VERSION "HIPBNYYYYYYYYYYYYYYYYYYYYYYYYYYYYYYYYYYYYY/4/%%%/4/'%**4YYY///"

NS_ :

BS_:

BU_: WS200 MCN_Powertrain Front_MCN Mid_MCN Rear_MCN IMU_MCN BIM1 BIM2 BIM3 BIM4 Computer BIM5 Rider_Controls

BO_ 1024 WS200IDInfo: 8 WS200
 SG_ TritiumID : 0|32@1+ (1,0) [0|0] "" Vector__XXX
 SG_ SerialNumber : 32|32@1+ (1,0) [0|0] "" Vector__XXX

BO_ 1025 WS200Status: 8 WS200
 SG_ ActiveMotor : 32|16@1+ (1,0) [0|0] "" Vector__XXX
 SG_ TransmitErrorCount : 48|8@1+ (1,0) [0|0] "" Vector__XXX
 SG_ ReceiveErrorCount : 56|8@1+ (1,0) [0|0] "" Vector__XXX
 SG_ HOCError : 16|1@1+ (1,0) [0|0] "" Vector__XXX
 SG_ SOCError : 17|1@1+ (1,0) [0|0] "" Vector__XXX
 SG_ DCBusOverLimit : 18|1@1+ (1,0) [0|0] "" Vector__XXX
 SG_ MotorPositionError : 19|1@1+ (1,0) [0|0] "" Vector__XXX
 SG_ Watchdog : 20|1@1+ (1,0) [0|0] "" Vector__XXX
 SG_ ConfigError : 21|1@1+ (1,0) [0|0] "" Vector__XXX
 SG_ UVLOError : 22|1@1+ (1,0) [0|0] "" Vector__XXX
 SG_ DesaturationFault : 23|1@1+ (1,0) [0|0] "" Vector__XXX
 SG_ OutputVoltageLimit : 0|1@1+ (1,0) [0|0] "" Vector__XXX
 SG_ MotorCurrentLimit : 1|1@1+ (1,0) [0|0] "" Vector__XXX
 SG_ VelocityLimit : 2|1@1+ (1,0) [0|0] "" Vector__XXX
 SG_ BusCurrentLimit : 3|1@1+ (1,0) [0|0] "" Vector__XXX
 SG_ BusVoltageUpperLimit : 4|1@1+ (1,0) [0|0] "" Vector__XXX
 SG_ BusVoltageLowerLimit : 5|1@1+ (1,0) [0|0] "" Vector__XXX
 SG_ MotorTempLimit : 6|1@1+ (1,0) [0|0] "" Vector__XXX

BO_ 1026 WS200BusMeasurement: 8 WS200
 SG_ BusVoltage : 0|32@1- (1,0) [0|0] "" Vector__XXX
 SG_ BusCurrent : 32|32@1- (1,0) [0|0] "" Vector__XXX

BO_ 1027 VelocityMeasurement: 8 WS200
 SG_ MotorVelocity : 0|32@1- (1,0) [0|0] "" Vector__XXX
 SG_ VehicleVelocity : 32|32@1- (1,0) [0|0] "" Vector__XXX

BO_ 1028 PhaseCurrent: 8 WS200
 SG_ PhaseCurrentB : 0|32@1- (1,0) [0|0] "" Vector__XXX
 SG_ PhaseCurrentC : 32|32@1- (1,0) [0|0] "" Vector__XXX

BO_ 1029 MotorVoltage: 8 WS200
 SG_ Vq : 0|32@1- (1,0) [0|0] "" Vector__XXX
 SG_ Vd : 32|32@1- (1,0) [0|0] "" Vector__XXX

BO_ 1030 MotorCurrent: 8 WS200
 SG_ Iq : 0|32@1- (1,0) [0|0] "" Vector__XXX
 SG_ Id : 32|32@1- (1,0) [0|0] "" Vector__XXX

BO_ 1031 MotorBackEMF: 8 WS200
 SG_ BEMFq : 0|32@1- (1,0) [0|0] "" Vector__XXX
 SG_ BEMFd : 32|32@1- (1,0) [0|0] "" Vector__XXX

BO_ 1032 WS200Rail15V: 8 WS200
 SG_ Supply15V : 32|32@1- (1,0) [0|0] "" Vector__XXX
 SG_ Reserved15V : 0|32@1- (1,0) [0|0] "" Vector__XXX

BO_ 1033 WS200LowRail: 8 WS200
 SG_ Rail2V : 0|32@1- (1,0) [0|0] "" Vector__XXX
 SG_ Rail3V : 32|32@1- (1,0) [0|0] "" Vector__XXX

BO_ 994 DynoCoolantFlow: 4 MCN_Powertrain
 SG_ CoolantFlow : 0|32@1- (1,0) [0|0] "" Vector__XXX

BO_ 995 DynoMotorCoolantTemp: 4 MCN_Powertrain
 SG_ MotorCoolantTemp : 0|32@1- (1,0) [0|0] "" Vector__XXX

BO_ 996 DynoMotorControllerCoolantTemp: 4 MCN_Powertrain
 SG_ MotorControllerCoolantTemp : 0|32@1- (1,0) [0|0] "" Vector__XXX

BO_ 997 DynoRadiatorCoolantTemp: 4 MCN_Powertrain
 SG_ RadiatorCoolantTemp : 0|32@1- (1,0) [0|0] "" Vector__XXX

BO_ 998 DynoCoolantPressures: 8 MCN_Powertrain
 SG_ CoolantPressure1 : 0|32@1- (1,0) [0|0] "" Vector__XXX
 SG_ CoolantPressure2 : 32|32@1- (1,0) [0|0] "" Vector__XXX

BO_ 100 DynLoc: 8 Computer
 SG_ Speed : 0|32@1- (1,0) [0|0] "MPH" Vector__XXX
 SG_ Torque : 32|32@1- (1,0) [0|0] "Nm" Vector__XXX

BO_ 999 DynoMCNStatus: 8 MCN_Powertrain
 SG_ DynoMCNSystemFlags : 0|32@1+ (1,0) [0|0] "" Vector__XXX
 SG_ DynoMCNUserFlags : 32|32@1+ (1,0) [0|0] "" Vector__XXX

BO_ 992 DynoAmbientTemp: 4 MCN_Powertrain
 SG_ DynoMCNAmbientTemp : 0|32@1- (1,0) [0|0] "" Vector__XXX

BO_ 991 DynoMotorTemp: 4 MCN_Powertrain
 SG_ DynoMCNMotorTemp : 0|32@1- (1,0) [0|0] "" Vector__XXX

BO_ 993 DynoMotorPlateTemps: 8 MCN_Powertrain
 SG_ DynoMotorPlateTemp1 : 0|32@1- (1,0) [0|0] "" Vector__XXX
 SG_ DynoMotorPlateTemp2 : 32|32@1- (1,0) [0|0] "" Vector__XXX

BO_ 1035 WS200MotorTemp: 8 WS200
 SG_ IPMPhaseATemp : 32|32@1- (1,0) [0|0] "" Vector__XXX
 SG_ MotorTemp : 0|32@1- (1,0) [0|0] "" Vector__XXX

BO_ 1036 WS200DSPBoardTemp: 8 WS200
 SG_ IPMPhaseBTemp : 0|32@1- (1,0) [0|0] "" Vector__XXX
 SG_ DSPBoardTemp : 32|32@1- (1,0) [0|0] "" Vector__XXX

BO_ 1037 WS200PhaseCTemp: 8 WS200
 SG_ IMPPhaseCTemp : 32|32@1- (1,0) [0|0] "" Vector__XXX
 SG_ Reserved : 0|32@1- (1,0) [0|0] "" Vector__XXX

BO_ 1038 WS200BusAmpHours: 8 WS200
 SG_ DCBusAmpHours : 32|32@1- (1,0) [0|0] "" Vector__XXX
 SG_ Odometer : 0|32@1- (1,0) [0|0] "" Vector__XXX

BO_ 1047 WS200SlipSpeed: 8 WS200
 SG_ SlipSpeed : 0|32@1- (1,0) [0|0] "" Vector__XXX
 SG_ Reserved : 32|32@1- (1,0) [0|0] "" Vector__XXX

BO_ 200 FrontSuspension: 4 Front_MCN
 SG_ FrontSuspensionTravel : 0|32@1- (1,0) [0|0] "" Vector__XXX

BO_ 201 Steering: 4 Front_MCN
 SG_ SteeringAngle : 0|32@1- (1,0) [0|0] "" Vector__XXX

BO_ 202 FrontWheel: 4 Front_MCN
 SG_ FrontWheelSpeed : 0|32@1- (1,0) [0|0] "" Vector__XXX

BO_ 203 FrontBrake: 4 Front_MCN
 SG_ FrontBrakePressure : 0|32@1- (1,0) [0|0] "" Vector__XXX

BO_ 204 FrontTire: 4 Front_MCN
 SG_ FrontTireTemp : 0|32@1- (1,0) [0|0] "" Vector__XXX

BO_ 205 AmbientMeasurements: 8 Front_MCN
 SG_ AmbientTemp : 0|32@1- (1,0) [0|0] "" Vector__XXX
 SG_ AmbientPressure : 32|32@1- (1,0) [0|0] "" Vector__XXX

BO_ 206 Radiator: 8 Front_MCN
 SG_ RadiatorAirPressure : 0|32@1- (1,0) [0|0] "" Vector__XXX
 SG_ RadiatorCoolantTemp : 32|32@1- (1,0) [0|0] "" Vector__XXX

BO_ 207 FrontMCNStatus: 8 Front_MCN
 SG_ FrontSystemFlags : 0|32@1- (1,0) [0|0] "" Vector__XXX
 SG_ FrontUserFlags : 32|32@1- (1,0) [0|0] "" Vector__XXX

BO_ 250 CoolantFlow: 4 Mid_MCN
 SG_ CoolantFlow : 0|32@1- (1,0) [0|0] "" Vector__XXX

BO_ 251 PowertrainCoolant: 8 Mid_MCN
 SG_ MotorCoolantTemp : 0|32@1- (1,0) [0|0] "" Vector__XXX
 SG_ ControllerCoolantTemp : 32|32@1- (1,0) [0|0] "" Vector__XXX

BO_ 252 MotorAirPressures: 4 Mid_MCN
 SG_ MotorAirPressure1 : 0|32@1- (1,0) [0|0] "" Vector__XXX
 SG_ MotorAirPressure2 : 32|32@1- (1,0) [0|0] "" Vector__XXX

BO_ 253 MotorPlateTemps: 8 Mid_MCN
 SG_ MotorPlateTemp1 : 0|32@1- (1,0) [0|0] "" Vector__XXX
 SG_ MotorPlateTemp2 : 32|32@1- (1,0) [0|0] "" Vector__XXX

BO_ 254 StrainGauges: 8 Mid_MCN
 SG_ StrainGauge1 : 0|32@1- (1,0) [0|0] "" Vector__XXX
 SG_ StrainGauge2 : 32|32@1- (1,0) [0|0] "" Vector__XXX

BO_ 257 MidMCNStatus: 8 Mid_MCN
 SG_ MidSystemFlags : 0|32@1- (1,0) [0|0] "" Vector__XXX
 SG_ MidUserFlags : 32|32@1- (1,0) [0|0] "" Vector__XXX

BO_ 300 RearSuspension: 4 Rear_MCN
 SG_ RearSuspensionTravel : 0|32@1- (1,0) [0|0] "" Vector__XXX

BO_ 301 RearWheelSpeed: 4 Rear_MCN
 SG_ RearWheelSpeed : 0|32@1- (1,0) [0|0] "" Vector__XXX

BO_ 302 RearTire: 4 Rear_MCN
 SG_ RearTireTemp : 0|32@1- (1,0) [0|0] "" Vector__XXX

BO_ 303 ContactorBox: 4 Rear_MCN
 SG_ ContactorBoxTemp : 0|32@1- (1,0) [0|0] "" Vector__XXX

BO_ 304 Shunts: 8 Rear_MCN
 SG_ ShuntHV : 0|32@1- (1,0) [0|0] "" Vector__XXX
 SG_ Shunt12V : 32|32@1- (1,0) [0|0] "" Vector__XXX

BO_ 305 FrameFault: 1 Rear_MCN
 SG_ FrameFault : 0|8@1+ (1,0) [0|0] "" Vector__XXX

BO_ 306 RearBrake: 4 Rear_MCN
 SG_ RearBrakePressure : 0|32@1- (1,0) [0|0] "" Vector__XXX

BO_ 307 RearMCNStatus: 8 Rear_MCN
 SG_ RearSystemsFlags : 0|32@1- (1,0) [0|0] "" Vector__XXX
 SG_ RearUserFlags : 32|32@1- (1,0) [0|0] "" Vector__XXX

BO_ 350 XAxisIMU: 8 IMU_MCN
 SG_ Roll : 0|32@1- (1,0) [0|0] "" Vector__XXX
 SG_ XAccelerometer : 32|32@1- (1,0) [0|0] "" Vector__XXX

BO_ 351 YAxisIMU: 8 IMU_MCN
 SG_ Pitch : 0|32@1- (1,0) [0|0] "" Vector__XXX
 SG_ YAccelerometer : 32|32@1- (1,0) [0|0] "" Vector__XXX

BO_ 352 ZAxisIMU: 8 IMU_MCN
 SG_ Yaw : 0|32@1- (1,0) [0|0] "" Vector__XXX
 SG_ ZAccelerometer : 32|32@1- (1,0) [0|0] "" Vector__XXX

BO_ 353 IMUMCNStatus: 8 IMU_MCN
 SG_ IMUSystemFlags : 0|32@1- (1,0) [0|0] "" Vector__XXX
 SG_ IMUUserFlags : 32|32@1- (1,0) [0|0] "" Vector__XXX

BO_ 1281 MotorDriveCommand: 8 Rider_Controls
 SG_ MotorRPMSetpoint : 0|32@1- (1,0) [0|4000] "" Vector__XXX
 SG_ MotorCurrentSetpoint : 32|32@1- (1,0) [0|1] "" Vector__XXX

BO_ 481 MotorPowerCommand: 8 Rider_Controls
 SG_ BusCurrentSetpoint : 32|32@1- (1,0) [0|1] "%" Vector__XXX

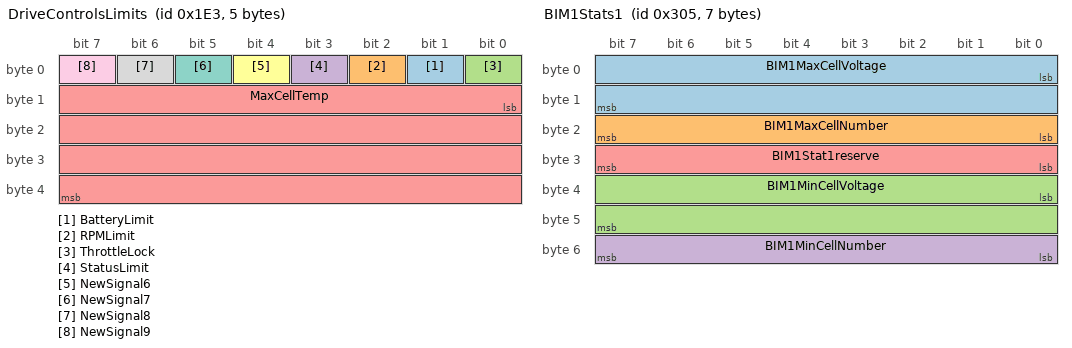
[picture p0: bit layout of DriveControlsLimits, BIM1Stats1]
BO_ 483 DriveControlsLimits: 5 Rider_Controls
 SG_ BatteryLimit : 1|1@1+ (1,0) [0|1] "" Vector__XXX
 SG_ RPMLimit : 2|1@1+ (1,0) [0|1] "" Vector__XXX
 SG_ ThrottleLock : 0|1@1+ (1,0) [0|0] "" Vector__XXX
 SG_ StatusLimit : 3|1@1+ (1,0) [0|0] "" Vector__XXX
 SG_ MaxCellTemp : 8|32@1- (1,0) [0|0] "" Vector__XXX
 SG_ NewSignal6 : 4|1@1+ (1,0) [0|0] "" Vector__XXX
 SG_ NewSignal7 : 5|1@1+ (1,0) [0|0] "" Vector__XXX
 SG_ NewSignal8 : 6|1@1+ (1,0) [0|0] "" Vector__XXX
 SG_ NewSignal9 : 7|1@1+ (1,0) [0|0] "" Vector__XXX

BO_ 773 BIM1Stats1: 7 BIM1
 SG_ BIM1MaxCellVoltage : 0|16@1+ (1,0) [0|0] "" Vector__XXX
 SG_ BIM1MaxCellNumber : 16|8@1+ (1,0) [0|0] "" Vector__XXX
 SG_ BIM1MinCellVoltage : 32|16@1+ (1,0) [0|0] "" Vector__XXX
 SG_ BIM1MinCellNumber : 48|8@1+ (1,0) [0|0] "" Vector__XXX
 SG_ BIM1Stat1reserve : 24|8@1+ (1,0) [0|0] "" Vector__XXX

BO_ 774 BIM1Stats2: 5 BIM1
 SG_ BIM1AvgCellVoltage : 0|16@1+ (1,0) [0|0] "" Vector__XXX
 SG_ BIM1StdDevVoltage : 16|16@1+ (1,0) [0|0] "" Vector__XXX
 SG_ BIM1BrickVoltage : 32|32@1+ (1,0) [0|0] "" Vector__XXX

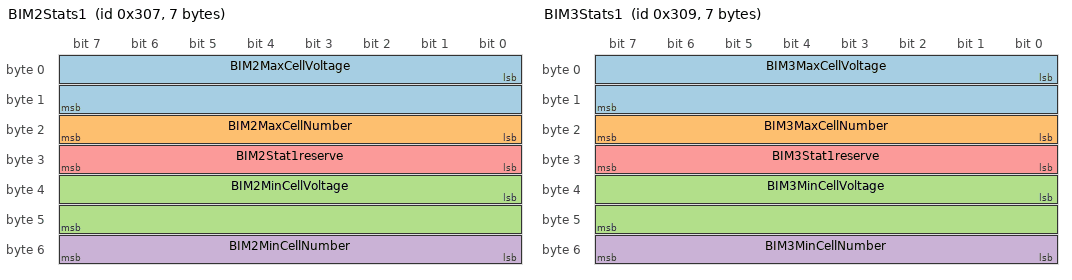
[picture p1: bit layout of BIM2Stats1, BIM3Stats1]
BO_ 775 BIM2Stats1: 7 BIM2
 SG_ BIM2MaxCellVoltage : 0|16@1+ (1,0) [0|0] "" Vector__XXX
 SG_ BIM2MaxCellNumber : 16|8@1+ (1,0) [0|0] "" Vector__XXX
 SG_ BIM2MinCellVoltage : 32|16@1+ (1,0) [0|0] "" Vector__XXX
 SG_ BIM2MinCellNumber : 48|8@1+ (1,0) [0|0] "" Vector__XXX
 SG_ BIM2Stat1reserve : 24|8@1+ (1,0) [0|0] "" Vector__XXX

BO_ 776 BIM2Stats2: 5 BIM2
 SG_ BIM2AvgCellVoltage : 0|16@1+ (1,0) [0|0] "" Vector__XXX
 SG_ BIM2StdDevVoltage : 16|16@1+ (1,0) [0|0] "" Vector__XXX
 SG_ BIM2BrickVoltage : 32|32@1+ (1,0) [0|0] "" Vector__XXX

BO_ 777 BIM3Stats1: 7 BIM3
 SG_ BIM3MaxCellVoltage : 0|16@1+ (1,0) [0|0] "" Vector__XXX
 SG_ BIM3MaxCellNumber : 16|8@1+ (1,0) [0|0] "" Vector__XXX
 SG_ BIM3MinCellVoltage : 32|16@1+ (1,0) [0|0] "" Vector__XXX
 SG_ BIM3MinCellNumber : 48|8@1+ (1,0) [0|0] "" Vector__XXX
 SG_ BIM3Stat1reserve : 24|8@1+ (1,0) [0|0] "" Vector__XXX

BO_ 778 BIM3Stats2: 5 BIM3
 SG_ BIM3AvgCellVoltage : 0|16@1+ (1,0) [0|0] "" Vector__XXX
 SG_ BIM3StdDevVoltage : 16|16@1+ (1,0) [0|0] "" Vector__XXX
 SG_ BIM3BrickVoltage : 32|32@1+ (1,0) [0|0] "" Vector__XXX

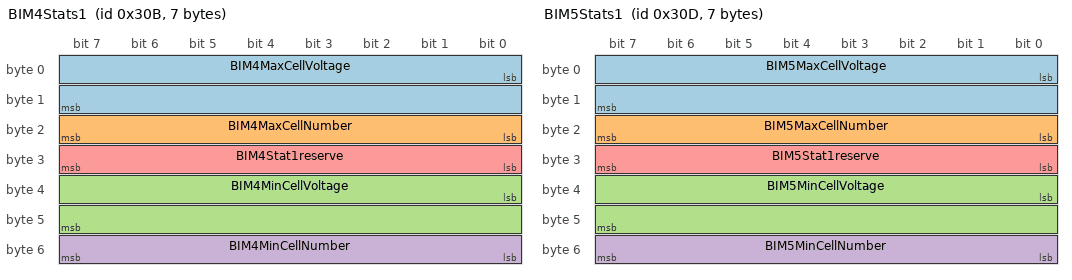
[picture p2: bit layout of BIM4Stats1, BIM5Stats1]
BO_ 779 BIM4Stats1: 7 BIM4
 SG_ BIM4MaxCellVoltage : 0|16@1+ (1,0) [0|0] "" Vector__XXX
 SG_ BIM4MaxCellNumber : 16|8@1+ (1,0) [0|0] "" Vector__XXX
 SG_ BIM4MinCellVoltage : 32|16@1+ (1,0) [0|0] "" Vector__XXX
 SG_ BIM4MinCellNumber : 48|8@1+ (1,0) [0|0] "" Vector__XXX
 SG_ BIM4Stat1reserve : 24|8@1+ (1,0) [0|0] "" Vector__XXX

BO_ 780 BIM4Stats2: 5 BIM4
 SG_ BIM4AvgCellVoltage : 0|16@1+ (1,0) [0|0] "" Vector__XXX
 SG_ BIM4StdDevVoltage : 16|16@1+ (1,0) [0|0] "" Vector__XXX
 SG_ BIM4BrickVoltage : 32|32@1+ (1,0) [0|0] "" Vector__XXX

BO_ 781 BIM5Stats1: 7 BIM5
 SG_ BIM5MaxCellVoltage : 0|16@1+ (1,0) [0|0] "" Vector__XXX
 SG_ BIM5MaxCellNumber : 16|8@1+ (1,0) [0|0] "" Vector__XXX
 SG_ BIM5MinCellVoltage : 32|16@1+ (1,0) [0|0] "" Vector__XXX
 SG_ BIM5MinCellNumber : 48|8@1+ (1,0) [0|0] "" Vector__XXX
 SG_ BIM5Stat1reserve : 24|8@1+ (1,0) [0|0] "" Vector__XXX

BO_ 782 BIM5Stats2: 5 BIM5
 SG_ BIM5AvgCellVoltage : 0|16@1+ (1,0) [0|0] "" Vector__XXX
 SG_ BIM5StdDevVoltage : 16|16@1+ (1,0) [0|0] "" Vector__XXX
 SG_ BIM5BrickVoltage : 32|32@1+ (1,0) [0|0] "" Vector__XXX

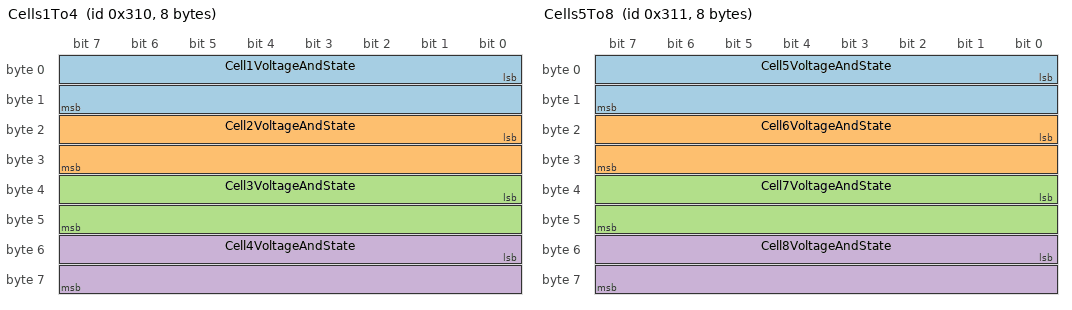
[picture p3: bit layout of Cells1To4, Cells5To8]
BO_ 784 Cells1To4: 8 BIM1
 SG_ Cell1VoltageAndState : 0|16@1- (1,0) [0|0] "" Vector__XXX
 SG_ Cell2VoltageAndState : 16|16@1- (1,0) [0|0] "" Vector__XXX
 SG_ Cell3VoltageAndState : 32|16@1- (1,0) [0|0] "" Vector__XXX
 SG_ Cell4VoltageAndState : 48|16@1- (1,0) [0|0] "" Vector__XXX

BO_ 785 Cells5To8: 8 BIM1
 SG_ Cell5VoltageAndState : 0|16@1- (1,0) [0|0] "" Vector__XXX
 SG_ Cell6VoltageAndState : 16|16@1- (1,0) [0|0] "" Vector__XXX
 SG_ Cell7VoltageAndState : 32|16@1- (1,0) [0|0] "" Vector__XXX
 SG_ Cell8VoltageAndState : 48|16@1- (1,0) [0|0] "" Vector__XXX

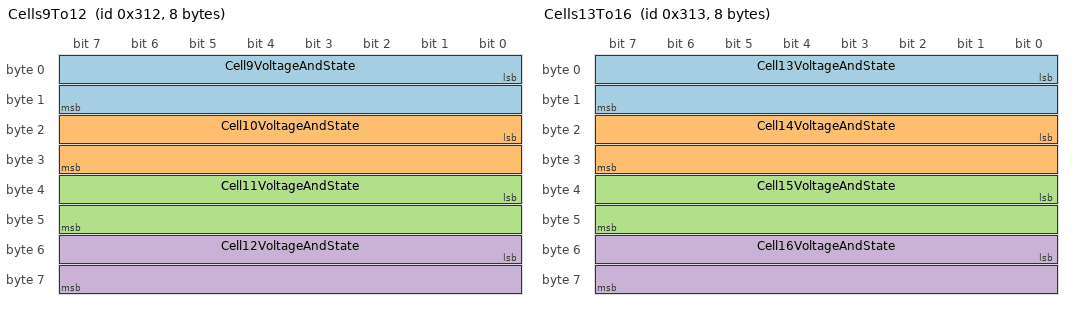
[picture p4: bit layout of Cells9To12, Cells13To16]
BO_ 786 Cells9To12: 8 BIM1
 SG_ Cell9VoltageAndState : 0|16@1- (1,0) [0|0] "" Vector__XXX
 SG_ Cell10VoltageAndState : 16|16@1- (1,0) [0|0] "" Vector__XXX
 SG_ Cell11VoltageAndState : 32|16@1- (1,0) [0|0] "" Vector__XXX
 SG_ Cell12VoltageAndState : 48|16@1- (1,0) [0|0] "" Vector__XXX

BO_ 787 Cells13To16: 8 BIM1
 SG_ Cell13VoltageAndState : 0|16@1- (1,0) [0|0] "" Vector__XXX
 SG_ Cell14VoltageAndState : 16|16@1- (1,0) [0|0] "" Vector__XXX
 SG_ Cell15VoltageAndState : 32|16@1- (1,0) [0|0] "" Vector__XXX
 SG_ Cell16VoltageAndState : 48|16@1- (1,0) [0|0] "" Vector__XXX

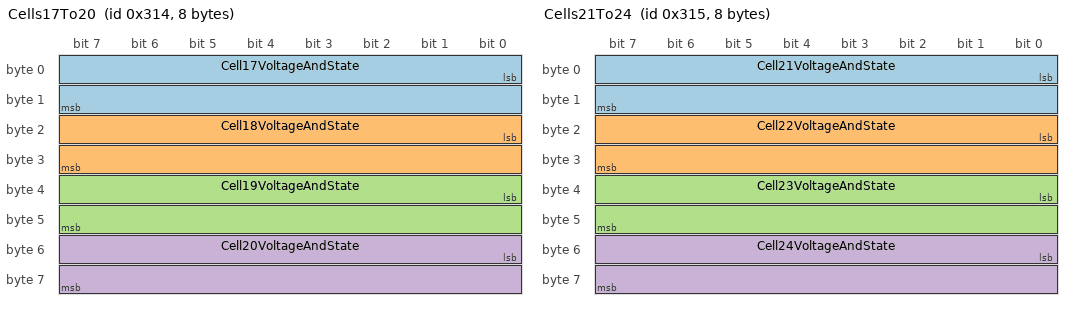
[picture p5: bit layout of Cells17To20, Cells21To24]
BO_ 788 Cells17To20: 8 BIM1
 SG_ Cell17VoltageAndState : 0|16@1- (1,0) [0|0] "" Vector__XXX
 SG_ Cell18VoltageAndState : 16|16@1- (1,0) [0|0] "" Vector__XXX
 SG_ Cell19VoltageAndState : 32|16@1- (1,0) [0|0] "" Vector__XXX
 SG_ Cell20VoltageAndState : 48|16@1- (1,0) [0|0] "" Vector__XXX

BO_ 789 Cells21To24: 8 BIM1
 SG_ Cell21VoltageAndState : 0|16@1- (1,0) [0|0] "" Vector__XXX
 SG_ Cell22VoltageAndState : 16|16@1- (1,0) [0|0] "" Vector__XXX
 SG_ Cell23VoltageAndState : 32|16@1- (1,0) [0|0] "" Vector__XXX
 SG_ Cell24VoltageAndState : 48|16@1- (1,0) [0|0] "" Vector__XXX

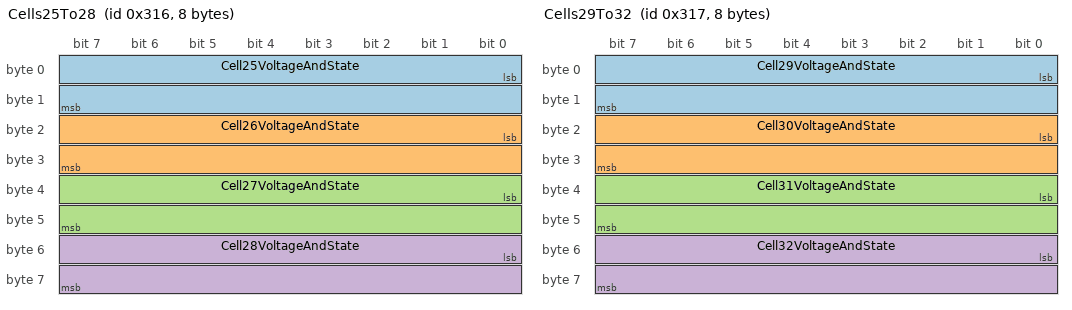
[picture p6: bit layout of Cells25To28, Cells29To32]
BO_ 790 Cells25To28: 8 BIM2
 SG_ Cell25VoltageAndState : 0|16@1- (1,0) [0|0] "" Vector__XXX
 SG_ Cell26VoltageAndState : 16|16@1- (1,0) [0|0] "" Vector__XXX
 SG_ Cell27VoltageAndState : 32|16@1- (1,0) [0|0] "" Vector__XXX
 SG_ Cell28VoltageAndState : 48|16@1- (1,0) [0|0] "" Vector__XXX

BO_ 791 Cells29To32: 8 BIM2
 SG_ Cell29VoltageAndState : 0|16@1- (1,0) [0|0] "" Vector__XXX
 SG_ Cell30VoltageAndState : 16|16@1- (1,0) [0|0] "" Vector__XXX
 SG_ Cell31VoltageAndState : 32|16@1- (1,0) [0|0] "" Vector__XXX
 SG_ Cell32VoltageAndState : 48|16@1- (1,0) [0|0] "" Vector__XXX

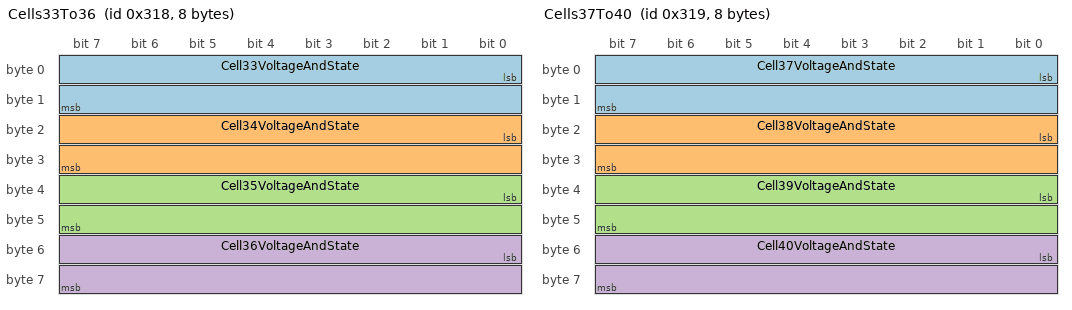
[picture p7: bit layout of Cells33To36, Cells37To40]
BO_ 792 Cells33To36: 8 BIM2
 SG_ Cell33VoltageAndState : 0|16@1- (1,0) [0|0] "" Vector__XXX
 SG_ Cell34VoltageAndState : 16|16@1- (1,0) [0|0] "" Vector__XXX
 SG_ Cell35VoltageAndState : 32|16@1- (1,0) [0|0] "" Vector__XXX
 SG_ Cell36VoltageAndState : 48|16@1- (1,0) [0|0] "" Vector__XXX

BO_ 793 Cells37To40: 8 BIM2
 SG_ Cell37VoltageAndState : 0|16@1- (1,0) [0|0] "" Vector__XXX
 SG_ Cell38VoltageAndState : 16|16@1- (1,0) [0|0] "" Vector__XXX
 SG_ Cell39VoltageAndState : 32|16@1- (1,0) [0|0] "" Vector__XXX
 SG_ Cell40VoltageAndState : 48|16@1- (1,0) [0|0] "" Vector__XXX

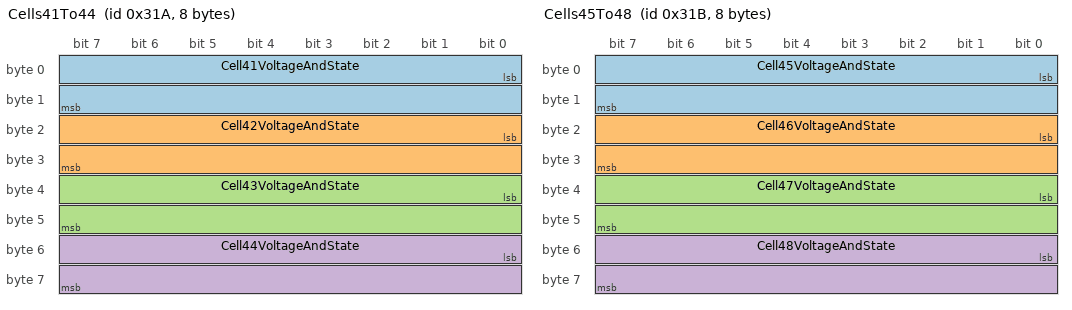
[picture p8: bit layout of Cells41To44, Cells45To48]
BO_ 794 Cells41To44: 8 BIM2
 SG_ Cell41VoltageAndState : 0|16@1- (1,0) [0|0] "" Vector__XXX
 SG_ Cell42VoltageAndState : 16|16@1- (1,0) [0|0] "" Vector__XXX
 SG_ Cell43VoltageAndState : 32|16@1- (1,0) [0|0] "" Vector__XXX
 SG_ Cell44VoltageAndState : 48|16@1- (1,0) [0|0] "" Vector__XXX

BO_ 795 Cells45To48: 8 BIM2
 SG_ Cell45VoltageAndState : 0|16@1- (1,0) [0|0] "" Vector__XXX
 SG_ Cell46VoltageAndState : 16|16@1- (1,0) [0|0] "" Vector__XXX
 SG_ Cell47VoltageAndState : 32|16@1- (1,0) [0|0] "" Vector__XXX
 SG_ Cell48VoltageAndState : 48|16@1- (1,0) [0|0] "" Vector__XXX

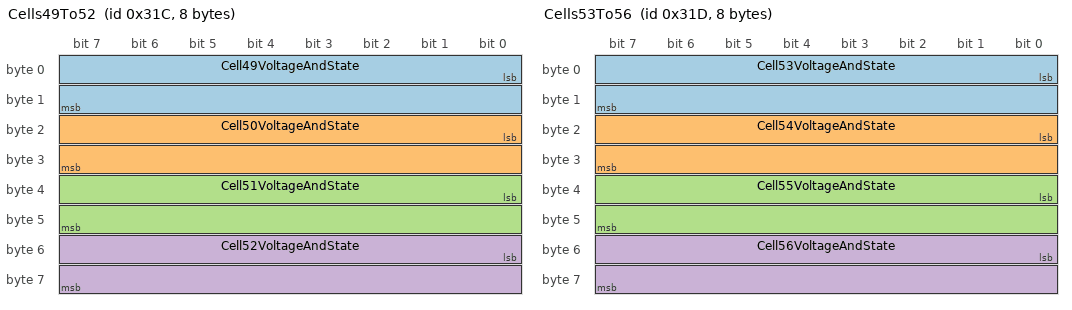
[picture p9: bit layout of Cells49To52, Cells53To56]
BO_ 796 Cells49To52: 8 BIM3
 SG_ Cell49VoltageAndState : 0|16@1- (1,0) [0|0] "" Vector__XXX
 SG_ Cell50VoltageAndState : 16|16@1- (1,0) [0|0] "" Vector__XXX
 SG_ Cell51VoltageAndState : 32|16@1- (1,0) [0|0] "" Vector__XXX
 SG_ Cell52VoltageAndState : 48|16@1- (1,0) [0|0] "" Vector__XXX

BO_ 797 Cells53To56: 8 BIM3
 SG_ Cell53VoltageAndState : 0|16@1- (1,0) [0|0] "" Vector__XXX
 SG_ Cell54VoltageAndState : 16|16@1- (1,0) [0|0] "" Vector__XXX
 SG_ Cell55VoltageAndState : 32|16@1- (1,0) [0|0] "" Vector__XXX
 SG_ Cell56VoltageAndState : 48|16@1- (1,0) [0|0] "" Vector__XXX

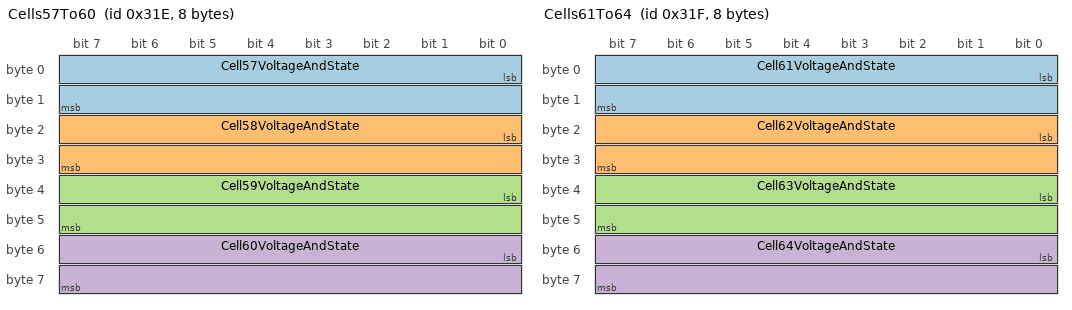
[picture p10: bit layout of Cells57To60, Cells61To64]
BO_ 798 Cells57To60: 8 BIM3
 SG_ Cell57VoltageAndState : 0|16@1- (1,0) [0|0] "" Vector__XXX
 SG_ Cell58VoltageAndState : 16|16@1- (1,0) [0|0] "" Vector__XXX
 SG_ Cell59VoltageAndState : 32|16@1- (1,0) [0|0] "" Vector__XXX
 SG_ Cell60VoltageAndState : 48|16@1- (1,0) [0|0] "" Vector__XXX

BO_ 799 Cells61To64: 8 BIM3
 SG_ Cell61VoltageAndState : 0|16@1- (1,0) [0|0] "" Vector__XXX
 SG_ Cell62VoltageAndState : 16|16@1- (1,0) [0|0] "" Vector__XXX
 SG_ Cell63VoltageAndState : 32|16@1- (1,0) [0|0] "" Vector__XXX
 SG_ Cell64VoltageAndState : 48|16@1- (1,0) [0|0] "" Vector__XXX

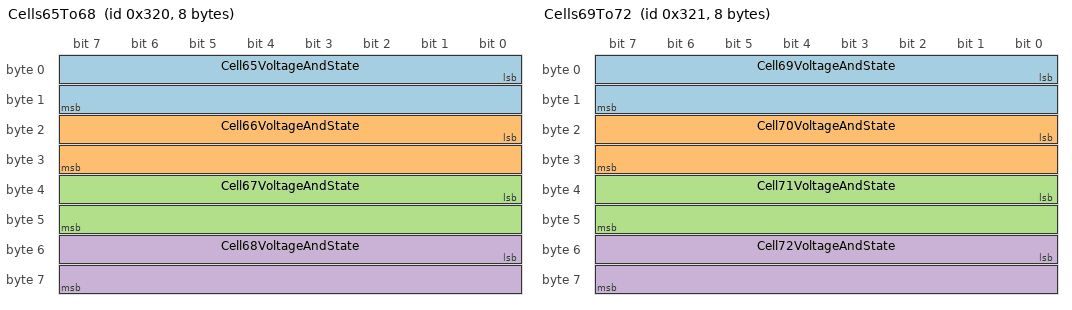
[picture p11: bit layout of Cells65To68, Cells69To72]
BO_ 800 Cells65To68: 8 BIM3
 SG_ Cell65VoltageAndState : 0|16@1- (1,0) [0|0] "" Vector__XXX
 SG_ Cell66VoltageAndState : 16|16@1- (1,0) [0|0] "" Vector__XXX
 SG_ Cell67VoltageAndState : 32|16@1- (1,0) [0|0] "" Vector__XXX
 SG_ Cell68VoltageAndState : 48|16@1- (1,0) [0|0] "" Vector__XXX

BO_ 801 Cells69To72: 8 BIM3
 SG_ Cell69VoltageAndState : 0|16@1- (1,0) [0|0] "" Vector__XXX
 SG_ Cell70VoltageAndState : 16|16@1- (1,0) [0|0] "" Vector__XXX
 SG_ Cell71VoltageAndState : 32|16@1- (1,0) [0|0] "" Vector__XXX
 SG_ Cell72VoltageAndState : 48|16@1- (1,0) [0|0] "" Vector__XXX

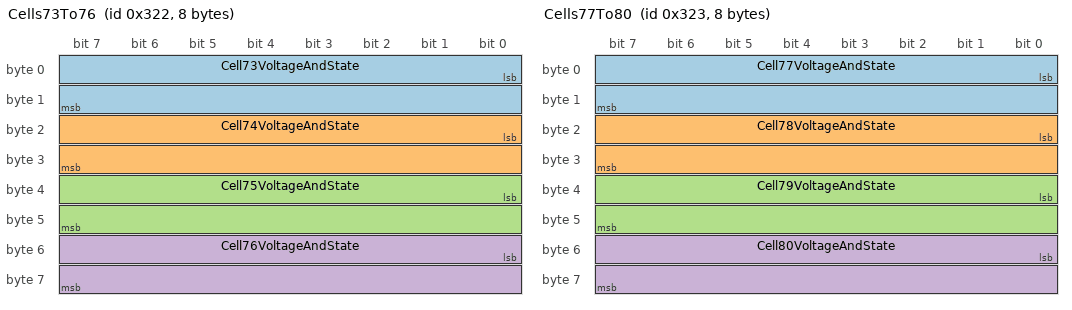
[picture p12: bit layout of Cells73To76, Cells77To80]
BO_ 802 Cells73To76: 8 BIM4
 SG_ Cell73VoltageAndState : 0|16@1- (1,0) [0|0] "" Vector__XXX
 SG_ Cell74VoltageAndState : 16|16@1- (1,0) [0|0] "" Vector__XXX
 SG_ Cell75VoltageAndState : 32|16@1- (1,0) [0|0] "" Vector__XXX
 SG_ Cell76VoltageAndState : 48|16@1- (1,0) [0|0] "" Vector__XXX

BO_ 803 Cells77To80: 8 BIM4
 SG_ Cell77VoltageAndState : 0|16@1- (1,0) [0|0] "" Vector__XXX
 SG_ Cell78VoltageAndState : 16|16@1- (1,0) [0|0] "" Vector__XXX
 SG_ Cell79VoltageAndState : 32|16@1- (1,0) [0|0] "" Vector__XXX
 SG_ Cell80VoltageAndState : 48|16@1- (1,0) [0|0] "" Vector__XXX

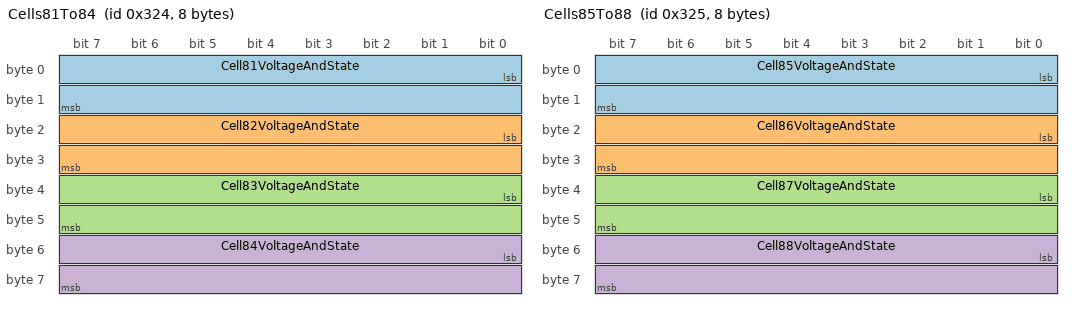
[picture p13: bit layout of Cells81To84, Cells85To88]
BO_ 804 Cells81To84: 8 BIM4
 SG_ Cell81VoltageAndState : 0|16@1- (1,0) [0|0] "" Vector__XXX
 SG_ Cell82VoltageAndState : 16|16@1- (1,0) [0|0] "" Vector__XXX
 SG_ Cell83VoltageAndState : 32|16@1- (1,0) [0|0] "" Vector__XXX
 SG_ Cell84VoltageAndState : 48|16@1- (1,0) [0|0] "" Vector__XXX

BO_ 805 Cells85To88: 8 BIM4
 SG_ Cell85VoltageAndState : 0|16@1- (1,0) [0|0] "" Vector__XXX
 SG_ Cell86VoltageAndState : 16|16@1- (1,0) [0|0] "" Vector__XXX
 SG_ Cell87VoltageAndState : 32|16@1- (1,0) [0|0] "" Vector__XXX
 SG_ Cell88VoltageAndState : 48|16@1- (1,0) [0|0] "" Vector__XXX

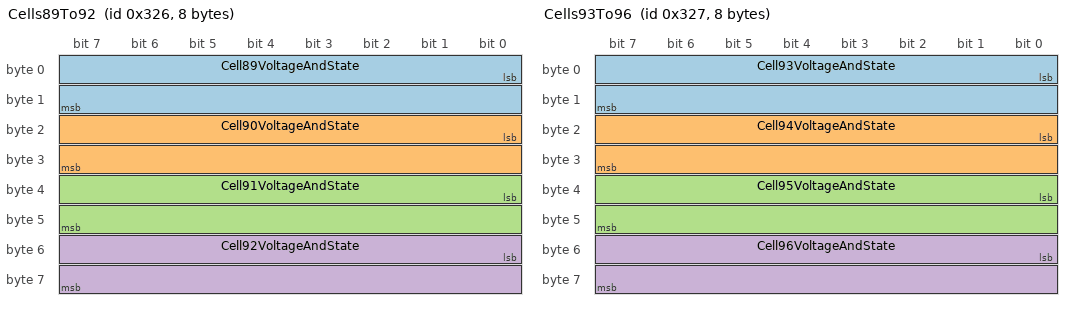
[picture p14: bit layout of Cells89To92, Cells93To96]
BO_ 806 Cells89To92: 8 BIM4
 SG_ Cell89VoltageAndState : 0|16@1- (1,0) [0|0] "" Vector__XXX
 SG_ Cell90VoltageAndState : 16|16@1- (1,0) [0|0] "" Vector__XXX
 SG_ Cell91VoltageAndState : 32|16@1- (1,0) [0|0] "" Vector__XXX
 SG_ Cell92VoltageAndState : 48|16@1- (1,0) [0|0] "" Vector__XXX

BO_ 807 Cells93To96: 8 BIM4
 SG_ Cell93VoltageAndState : 0|16@1- (1,0) [0|0] "" Vector__XXX
 SG_ Cell94VoltageAndState : 16|16@1- (1,0) [0|0] "" Vector__XXX
 SG_ Cell95VoltageAndState : 32|16@1- (1,0) [0|0] "" Vector__XXX
 SG_ Cell96VoltageAndState : 48|16@1- (1,0) [0|0] "" Vector__XXX

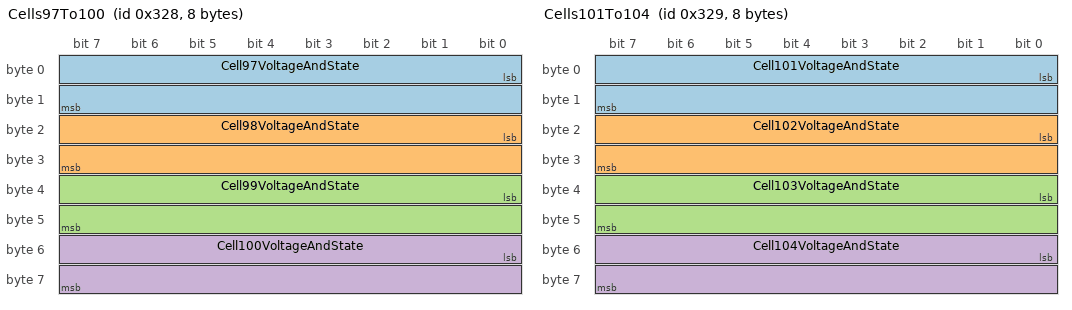
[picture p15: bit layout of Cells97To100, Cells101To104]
BO_ 808 Cells97To100: 8 BIM5
 SG_ Cell97VoltageAndState : 0|16@1- (1,0) [0|0] "" Vector__XXX
 SG_ Cell98VoltageAndState : 16|16@1- (1,0) [0|0] "" Vector__XXX
 SG_ Cell99VoltageAndState : 32|16@1- (1,0) [0|0] "" Vector__XXX
 SG_ Cell100VoltageAndState : 48|16@1- (1,0) [0|0] "" Vector__XXX

BO_ 809 Cells101To104: 8 BIM5
 SG_ Cell101VoltageAndState : 0|16@1- (1,0) [0|0] "" Vector__XXX
 SG_ Cell102VoltageAndState : 16|16@1- (1,0) [0|0] "" Vector__XXX
 SG_ Cell103VoltageAndState : 32|16@1- (1,0) [0|0] "" Vector__XXX
 SG_ Cell104VoltageAndState : 48|16@1- (1,0) [0|0] "" Vector__XXX

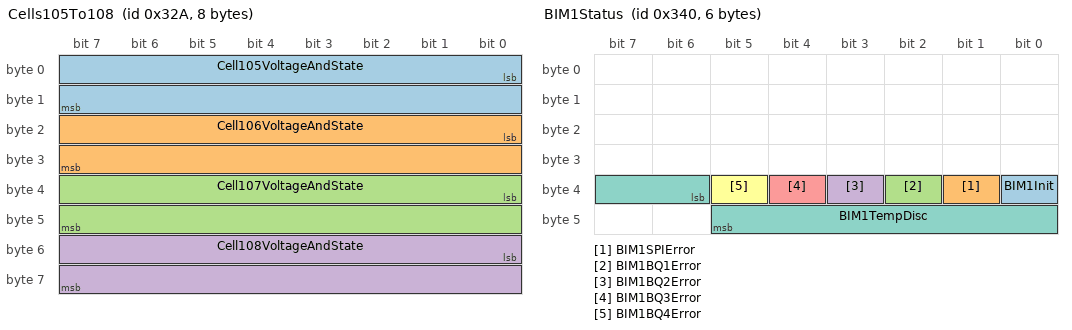
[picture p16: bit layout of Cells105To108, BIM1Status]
BO_ 810 Cells105To108: 8 BIM5
 SG_ Cell105VoltageAndState : 0|16@1- (1,0) [0|0] "" Vector__XXX
 SG_ Cell106VoltageAndState : 16|16@1- (1,0) [0|0] "" Vector__XXX
 SG_ Cell107VoltageAndState : 32|16@1- (1,0) [0|0] "" Vector__XXX
 SG_ Cell108VoltageAndState : 48|16@1- (1,0) [0|0] "" Vector__XXX

BO_ 812 CellTemp1: 8 BIM1
 SG_ CellTemp1 : 0|32@1- (1,0) [0|0] "" Vector__XXX
 SG_ CellTemp2 : 32|32@1- (1,0) [0|0] "" Vector__XXX

BO_ 813 CellTemp2: 8 BIM1
 SG_ CellTemp3 : 0|32@1- (1,0) [0|0] "" Vector__XXX
 SG_ CellTemp4 : 32|32@1- (1,0) [0|0] "" Vector__XXX

BO_ 814 CellTemp3: 8 BIM1
 SG_ CellTemp5 : 0|32@1- (1,0) [0|0] "" Vector__XXX
 SG_ CellTemp6 : 32|32@1- (1,0) [0|0] "" Vector__XXX

BO_ 815 CellTemp4: 8 BIM1
 SG_ CellTemp7 : 0|32@1- (1,0) [0|0] "" Vector__XXX
 SG_ CellTemp8 : 32|32@1- (1,0) [0|0] "" Vector__XXX

BO_ 816 CellTemp5: 8 BIM2
 SG_ CellTemp9 : 0|32@1- (1,0) [0|0] "" Vector__XXX
 SG_ CellTemp10 : 32|32@1- (1,0) [0|0] "" Vector__XXX

BO_ 817 CellTemp6: 8 BIM2
 SG_ CellTemp11 : 0|32@1- (1,0) [0|0] "" Vector__XXX
 SG_ CellTemp12 : 32|32@1- (1,0) [0|0] "" Vector__XXX

BO_ 818 CellTemp7: 8 BIM2
 SG_ CellTemp13 : 0|32@1- (1,0) [0|0] "" Vector__XXX
 SG_ CellTemp14 : 32|32@1- (1,0) [0|0] "" Vector__XXX

BO_ 819 CellTemp8: 8 BIM2
 SG_ CellTemp15 : 0|32@1- (1,0) [0|0] "" Vector__XXX
 SG_ CellTemp16 : 32|32@1- (1,0) [0|0] "" Vector__XXX

BO_ 820 CellTemp9: 8 BIM3
 SG_ CellTemp17 : 0|32@1- (1,0) [0|0] "" Vector__XXX
 SG_ CellTemp18 : 32|32@1- (1,0) [0|0] "" Vector__XXX

BO_ 821 CellTemp10: 8 BIM3
 SG_ CellTemp19 : 0|32@1- (1,0) [0|0] "" Vector__XXX
 SG_ CellTemp20 : 32|32@1- (1,0) [0|0] "" Vector__XXX

BO_ 822 CellTemp11: 8 BIM3
 SG_ CellTemp21 : 0|32@1- (1,0) [0|0] "" Vector__XXX
 SG_ CellTemp22 : 32|32@1- (1,0) [0|0] "" Vector__XXX

BO_ 823 CellTemp12: 8 BIM3
 SG_ CellTemp23 : 0|32@1- (1,0) [0|0] "" Vector__XXX
 SG_ CellTemp24 : 32|32@1- (1,0) [0|0] "" Vector__XXX

BO_ 824 CellTemp13: 8 BIM4
 SG_ CellTemp25 : 0|32@1- (1,0) [0|0] "" Vector__XXX
 SG_ CellTemp26 : 32|32@1- (1,0) [0|0] "" Vector__XXX

BO_ 825 CellTemp14: 8 BIM4
 SG_ CellTemp27 : 0|32@1- (1,0) [0|0] "" Vector__XXX
 SG_ CellTemp28 : 32|32@1- (1,0) [0|0] "" Vector__XXX

BO_ 826 CellTemp15: 8 BIM4
 SG_ CellTemp29 : 0|32@1- (1,0) [0|0] "" Vector__XXX
 SG_ CellTemp30 : 32|32@1- (1,0) [0|0] "" Vector__XXX

BO_ 827 CellTemp16: 8 BIM4
 SG_ CellTemp31 : 0|32@1- (1,0) [0|0] "" Vector__XXX
 SG_ CellTemp32 : 32|32@1- (1,0) [0|0] "" Vector__XXX

BO_ 828 CellTemp17: 8 BIM5
 SG_ CellTemp33 : 0|32@1- (1,0) [0|0] "" Vector__XXX
 SG_ CellTemp34 : 32|32@1- (1,0) [0|0] "" Vector__XXX

BO_ 829 CellTemp18: 8 BIM5
 SG_ CellTemp35 : 0|32@1- (1,0) [0|0] "" Vector__XXX
 SG_ CellTemp36 : 32|32@1- (1,0) [0|0] "" Vector__XXX

BO_ 830 CellTemp19: 8 BIM5
 SG_ CellTemp37 : 0|32@1- (1,0) [0|0] "" Vector__XXX
 SG_ CellTemp38 : 32|32@1- (1,0) [0|0] "" Vector__XXX

BO_ 831 CellTemp20: 8 BIM5
 SG_ CellTemp39 : 0|32@1- (1,0) [0|0] "" Vector__XXX
 SG_ CellTemp40 : 32|32@1- (1,0) [0|0] "" Vector__XXX

BO_ 832 BIM1Status: 6 BIM1
 SG_ BIM1Init : 32|1@1+ (1,0) [0|0] "" Vector__XXX
 SG_ BIM1SPIError : 33|1@1+ (1,0) [0|0] "" Vector__XXX
 SG_ BIM1BQ1Error : 34|1@1+ (1,0) [0|0] "" Vector__XXX
 SG_ BIM1BQ2Error : 35|1@1+ (1,0) [0|0] "" Vector__XXX
 SG_ BIM1BQ3Error : 36|1@1+ (1,0) [0|0] "" Vector__XXX
 SG_ BIM1BQ4Error : 37|1@1+ (1,0) [0|0] "" Vector__XXX
 SG_ BIM1TempDisc : 38|8@1+ (1,0) [0|0] "" Vector__XXX

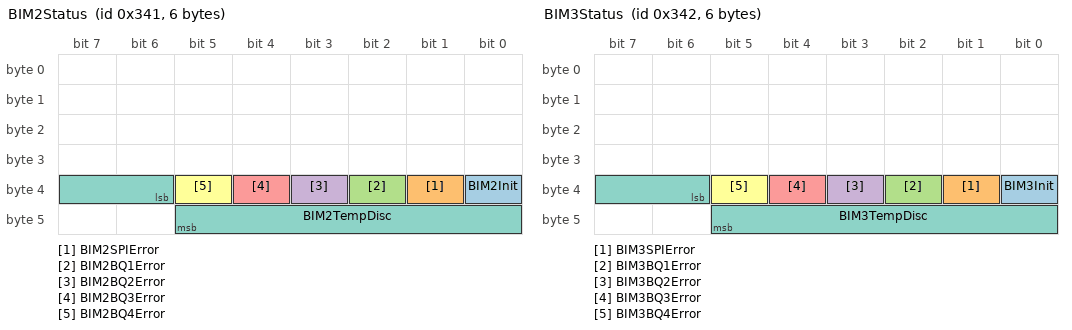
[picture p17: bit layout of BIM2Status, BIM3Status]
BO_ 833 BIM2Status: 6 BIM2
 SG_ BIM2Init : 32|1@1+ (1,0) [0|0] "" Vector__XXX
 SG_ BIM2SPIError : 33|1@1+ (1,0) [0|0] "" Vector__XXX
 SG_ BIM2BQ1Error : 34|1@1+ (1,0) [0|0] "" Vector__XXX
 SG_ BIM2BQ2Error : 35|1@1+ (1,0) [0|0] "" Vector__XXX
 SG_ BIM2BQ3Error : 36|1@1+ (1,0) [0|0] "" Vector__XXX
 SG_ BIM2BQ4Error : 37|1@1+ (1,0) [0|0] "" Vector__XXX
 SG_ BIM2TempDisc : 38|8@1+ (1,0) [0|0] "" Vector__XXX

BO_ 834 BIM3Status: 6 BIM3
 SG_ BIM3Init : 32|1@1+ (1,0) [0|0] "" Vector__XXX
 SG_ BIM3SPIError : 33|1@1+ (1,0) [0|0] "" Vector__XXX
 SG_ BIM3BQ1Error : 34|1@1+ (1,0) [0|0] "" Vector__XXX
 SG_ BIM3BQ2Error : 35|1@1+ (1,0) [0|0] "" Vector__XXX
 SG_ BIM3BQ3Error : 36|1@1+ (1,0) [0|0] "" Vector__XXX
 SG_ BIM3BQ4Error : 37|1@1+ (1,0) [0|0] "" Vector__XXX
 SG_ BIM3TempDisc : 38|8@1+ (1,0) [0|0] "" Vector__XXX

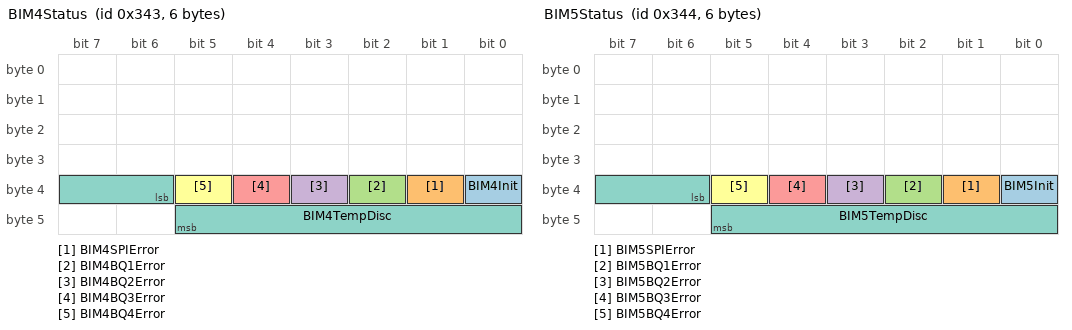
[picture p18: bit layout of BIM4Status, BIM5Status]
BO_ 835 BIM4Status: 6 BIM4
 SG_ BIM4Init : 32|1@1+ (1,0) [0|0] "" Vector__XXX
 SG_ BIM4SPIError : 33|1@1+ (1,0) [0|0] "" Vector__XXX
 SG_ BIM4BQ1Error : 34|1@1+ (1,0) [0|0] "" Vector__XXX
 SG_ BIM4BQ2Error : 35|1@1+ (1,0) [0|0] "" Vector__XXX
 SG_ BIM4BQ3Error : 36|1@1+ (1,0) [0|0] "" Vector__XXX
 SG_ BIM4BQ4Error : 37|1@1+ (1,0) [0|0] "" Vector__XXX
 SG_ BIM4TempDisc : 38|8@1+ (1,0) [0|0] "" Vector__XXX

BO_ 836 BIM5Status: 6 BIM5
 SG_ BIM5Init : 32|1@1+ (1,0) [0|0] "" Vector__XXX
 SG_ BIM5SPIError : 33|1@1+ (1,0) [0|0] "" Vector__XXX
 SG_ BIM5BQ1Error : 34|1@1+ (1,0) [0|0] "" Vector__XXX
 SG_ BIM5BQ2Error : 35|1@1+ (1,0) [0|0] "" Vector__XXX
 SG_ BIM5BQ3Error : 36|1@1+ (1,0) [0|0] "" Vector__XXX
 SG_ BIM5BQ4Error : 37|1@1+ (1,0) [0|0] "" Vector__XXX
 SG_ BIM5TempDisc : 38|8@1+ (1,0) [0|0] "" Vector__XXX

BO_ 355 GPS_Alt_Accur: 8 IMU_MCN
 SG_ Altitude : 32|32@1- (1,0) [0|0] "" Vector__XXX
 SG_ PDOP : 0|32@1- (1,0) [0|0] "" Vector__XXX

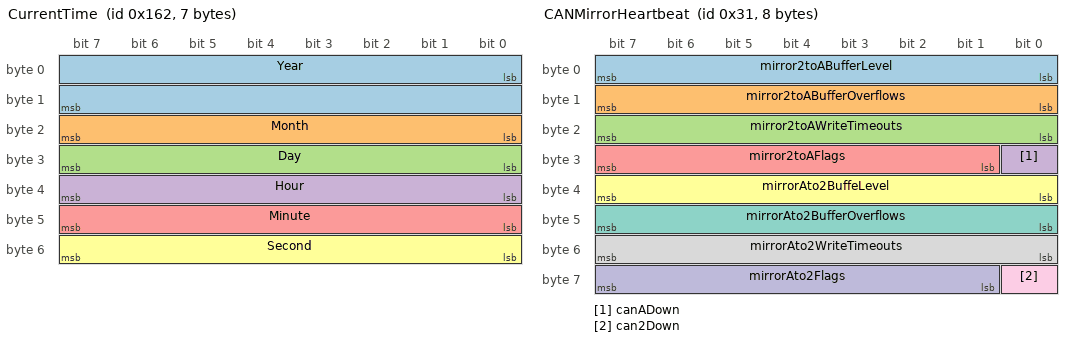
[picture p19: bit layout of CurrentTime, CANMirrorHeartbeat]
BO_ 354 CurrentTime: 7 IMU_MCN
 SG_ Year : 0|16@1- (1,0) [0|0] "" Vector__XXX
 SG_ Month : 16|8@1- (1,0) [0|0] "" Vector__XXX
 SG_ Day : 24|8@1- (1,0) [0|0] "" Vector__XXX
 SG_ Hour : 32|8@1- (1,0) [0|0] "" Vector__XXX
 SG_ Minute : 40|8@1- (1,0) [0|0] "" Vector__XXX
 SG_ Second : 48|8@1- (1,0) [0|0] "" Vector__XXX

BO_ 356 GPS_Lat_Val: 8 IMU_MCN
 SG_ Latitude : 0|32@1- (1,0) [0|0] "" Vector__XXX
 SG_ GPSvalid : 32|32@1+ (1,0) [0|0] "" Vector__XXX

BO_ 357 GPS_Long: 8 IMU_MCN
 SG_ Longitude : 0|32@1- (1,0) [0|0] "" Vector__XXX
 SG_ LongReserv : 32|32@1- (1,0) [0|0] "" Vector__XXX

BO_ 358 GPS_Speed: 8 IMU_MCN
 SG_ Speed : 0|32@1- (1,0) [0|0] "" Vector__XXX
 SG_ SpeedReserv : 32|32@1- (1,0) [0|0] "" Vector__XXX

BO_ 49 CANMirrorHeartbeat: 8 Vector__XXX
 SG_ mirror2toABufferLevel : 0|8@1+ (1,0) [0|0] "" Vector__XXX
 SG_ mirror2toABufferOverflows : 8|8@1+ (1,0) [0|0] "" Vector__XXX
 SG_ mirror2toAWriteTimeouts : 16|8@1+ (1,0) [0|0] "" Vector__XXX
 SG_ canADown : 24|1@1+ (1,0) [0|0] "" Vector__XXX
 SG_ mirror2toAFlags : 25|7@1+ (1,0) [0|0] "" Vector__XXX
 SG_ mirrorAto2BuffeLevel : 32|8@1+ (1,0) [0|0] "" Vector__XXX
 SG_ mirrorAto2BufferOverflows : 40|8@1+ (1,0) [0|0] "" Vector__XXX
 SG_ mirrorAto2WriteTimeouts : 48|8@1+ (1,0) [0|0] "" Vector__XXX
 SG_ can2Down : 56|1@1+ (1,0) [0|0] "" Vector__XXX
 SG_ mirrorAto2Flags : 57|7@1+ (1,0) [0|0] "" Vector__XXX

BO_ 1283 WS200Reset: 1 WS200
 SG_ TritiumReset : 0|8@1+ (1,0) [0|0] "" Vector__XXX

BO_ 1284 Supply12vMsg: 4 Vector__XXX
 SG_ Supply12v : 0|32@1- (1,0) [0|0] "" Vector__XXX

BO_ 484 DriveControlsThrottle: 8 Vector__XXX
 SG_ RawThrottle : 0|32@1- (1,0) [0|0] "" Vector__XXX

CM_ SG_ 1025 ActiveMotor "[0,10]";
CM_ SG_ 100 Speed "[-10,10]";
CM_ SG_ 100 Torque "[-20,50]";
CM_ BO_ 784 "RTR";
CM_ BO_ 785 "RTR";
CM_ BO_ 786 "RTR";
CM_ BO_ 787 "RTR";
CM_ BO_ 788 "RTR";
CM_ BO_ 789 "RTR";
CM_ BO_ 790 "RTR";
CM_ BO_ 791 "RTR";
CM_ BO_ 792 "RTR";
CM_ BO_ 793 "RTR";
CM_ BO_ 794 "RTR";
CM_ BO_ 795 "RTR";
CM_ BO_ 796 "RTR";
CM_ BO_ 797 "RTR";
CM_ BO_ 798 "RTR";
CM_ BO_ 799 "RTR";
CM_ BO_ 800 "RTR";
CM_ BO_ 801 "RTR";
CM_ BO_ 802 "RTR";
CM_ BO_ 803 "RTR";
CM_ BO_ 804 "RTR";
CM_ BO_ 805 "RTR";
CM_ BO_ 806 "RTR";
CM_ BO_ 807 "RTR";
CM_ BO_ 808 "RTR";
CM_ BO_ 809 "RTR";
CM_ BO_ 810 "RTR";
SIG_VALTYPE_ 1026 BusVoltage : 1;
SIG_VALTYPE_ 1026 BusCurrent : 1;
SIG_VALTYPE_ 1027 MotorVelocity : 1;
SIG_VALTYPE_ 1027 VehicleVelocity : 1;
SIG_VALTYPE_ 1028 PhaseCurrentB : 1;
SIG_VALTYPE_ 1028 PhaseCurrentC : 1;
SIG_VALTYPE_ 1029 Vq : 1;
SIG_VALTYPE_ 1029 Vd : 1;
SIG_VALTYPE_ 1030 Iq : 1;
SIG_VALTYPE_ 1030 Id : 1;
SIG_VALTYPE_ 1031 BEMFq : 1;
SIG_VALTYPE_ 1031 BEMFd : 1;
SIG_VALTYPE_ 1032 Supply15V : 1;
SIG_VALTYPE_ 1032 Reserved15V : 1;
SIG_VALTYPE_ 1033 Rail2V : 1;
SIG_VALTYPE_ 1033 Rail3V : 1;
SIG_VALTYPE_ 994 CoolantFlow : 1;
SIG_VALTYPE_ 995 MotorCoolantTemp : 1;
SIG_VALTYPE_ 996 MotorControllerCoolantTemp : 1;
SIG_VALTYPE_ 997 RadiatorCoolantTemp : 1;
SIG_VALTYPE_ 998 CoolantPressure1 : 1;
SIG_VALTYPE_ 998 CoolantPressure2 : 1;
SIG_VALTYPE_ 100 Speed : 1;
SIG_VALTYPE_ 100 Torque : 1;
SIG_VALTYPE_ 992 DynoMCNAmbientTemp : 1;
SIG_VALTYPE_ 991 DynoMCNMotorTemp : 1;
SIG_VALTYPE_ 993 DynoMotorPlateTemp1 : 1;
SIG_VALTYPE_ 993 DynoMotorPlateTemp2 : 1;
SIG_VALTYPE_ 1035 IPMPhaseATemp : 1;
SIG_VALTYPE_ 1035 MotorTemp : 1;
SIG_VALTYPE_ 1036 IPMPhaseBTemp : 1;
SIG_VALTYPE_ 1036 DSPBoardTemp : 1;
SIG_VALTYPE_ 1037 IMPPhaseCTemp : 1;
SIG_VALTYPE_ 1037 Reserved : 1;
SIG_VALTYPE_ 1038 DCBusAmpHours : 1;
SIG_VALTYPE_ 1038 Odometer : 1;
SIG_VALTYPE_ 1047 SlipSpeed : 1;
SIG_VALTYPE_ 1047 Reserved : 1;
SIG_VALTYPE_ 200 FrontSuspensionTravel : 1;
SIG_VALTYPE_ 201 SteeringAngle : 1;
SIG_VALTYPE_ 202 FrontWheelSpeed : 1;
SIG_VALTYPE_ 203 FrontBrakePressure : 1;
SIG_VALTYPE_ 204 FrontTireTemp : 1;
SIG_VALTYPE_ 205 AmbientTemp : 1;
SIG_VALTYPE_ 205 AmbientPressure : 1;
SIG_VALTYPE_ 206 RadiatorAirPressure : 1;
SIG_VALTYPE_ 206 RadiatorCoolantTemp : 1;
SIG_VALTYPE_ 207 FrontSystemFlags : 1;
SIG_VALTYPE_ 207 FrontUserFlags : 1;
SIG_VALTYPE_ 250 CoolantFlow : 1;
SIG_VALTYPE_ 251 MotorCoolantTemp : 1;
SIG_VALTYPE_ 251 ControllerCoolantTemp : 1;
SIG_VALTYPE_ 252 MotorAirPressure1 : 1;
SIG_VALTYPE_ 252 MotorAirPressure2 : 1;
SIG_VALTYPE_ 253 MotorPlateTemp1 : 1;
SIG_VALTYPE_ 253 MotorPlateTemp2 : 1;
SIG_VALTYPE_ 254 StrainGauge1 : 1;
SIG_VALTYPE_ 254 StrainGauge2 : 1;
SIG_VALTYPE_ 257 MidSystemFlags : 1;
SIG_VALTYPE_ 257 MidUserFlags : 1;
SIG_VALTYPE_ 300 RearSuspensionTravel : 1;
SIG_VALTYPE_ 301 RearWheelSpeed : 1;
SIG_VALTYPE_ 302 RearTireTemp : 1;
SIG_VALTYPE_ 303 ContactorBoxTemp : 1;
SIG_VALTYPE_ 304 ShuntHV : 1;
SIG_VALTYPE_ 304 Shunt12V : 1;
SIG_VALTYPE_ 306 RearBrakePressure : 1;
SIG_VALTYPE_ 307 RearSystemsFlags : 1;
SIG_VALTYPE_ 307 RearUserFlags : 1;
SIG_VALTYPE_ 350 Roll : 1;
SIG_VALTYPE_ 350 XAccelerometer : 1;
SIG_VALTYPE_ 351 Pitch : 1;
SIG_VALTYPE_ 351 YAccelerometer : 1;
SIG_VALTYPE_ 352 Yaw : 1;
SIG_VALTYPE_ 352 ZAccelerometer : 1;
SIG_VALTYPE_ 353 IMUSystemFlags : 1;
SIG_VALTYPE_ 353 IMUUserFlags : 1;
SIG_VALTYPE_ 1281 MotorRPMSetpoint : 1;
SIG_VALTYPE_ 1281 MotorCurrentSetpoint : 1;
SIG_VALTYPE_ 481 BusCurrentSetpoint : 1;
SIG_VALTYPE_ 483 MaxCellTemp : 1;
SIG_VALTYPE_ 812 CellTemp1 : 1;
SIG_VALTYPE_ 812 CellTemp2 : 1;
SIG_VALTYPE_ 813 CellTemp3 : 1;
SIG_VALTYPE_ 813 CellTemp4 : 1;
SIG_VALTYPE_ 814 CellTemp5 : 1;
SIG_VALTYPE_ 814 CellTemp6 : 1;
SIG_VALTYPE_ 815 CellTemp7 : 1;
SIG_VALTYPE_ 815 CellTemp8 : 1;
SIG_VALTYPE_ 816 CellTemp9 : 1;
SIG_VALTYPE_ 816 CellTemp10 : 1;
SIG_VALTYPE_ 817 CellTemp11 : 1;
SIG_VALTYPE_ 817 CellTemp12 : 1;
SIG_VALTYPE_ 818 CellTemp13 : 1;
SIG_VALTYPE_ 818 CellTemp14 : 1;
SIG_VALTYPE_ 819 CellTemp15 : 1;
SIG_VALTYPE_ 819 CellTemp16 : 1;
SIG_VALTYPE_ 820 CellTemp17 : 1;
SIG_VALTYPE_ 820 CellTemp18 : 1;
SIG_VALTYPE_ 821 CellTemp19 : 1;
SIG_VALTYPE_ 821 CellTemp20 : 1;
SIG_VALTYPE_ 822 CellTemp21 : 1;
SIG_VALTYPE_ 822 CellTemp22 : 1;
SIG_VALTYPE_ 823 CellTemp23 : 1;
SIG_VALTYPE_ 823 CellTemp24 : 1;
SIG_VALTYPE_ 824 CellTemp25 : 1;
SIG_VALTYPE_ 824 CellTemp26 : 1;
SIG_VALTYPE_ 825 CellTemp27 : 1;
SIG_VALTYPE_ 825 CellTemp28 : 1;
SIG_VALTYPE_ 826 CellTemp29 : 1;
SIG_VALTYPE_ 826 CellTemp30 : 1;
SIG_VALTYPE_ 827 CellTemp31 : 1;
SIG_VALTYPE_ 827 CellTemp32 : 1;
SIG_VALTYPE_ 828 CellTemp33 : 1;
SIG_VALTYPE_ 828 CellTemp34 : 1;
SIG_VALTYPE_ 829 CellTemp35 : 1;
SIG_VALTYPE_ 829 CellTemp36 : 1;
SIG_VALTYPE_ 830 CellTemp37 : 1;
SIG_VALTYPE_ 830 CellTemp38 : 1;
SIG_VALTYPE_ 831 CellTemp39 : 1;
SIG_VALTYPE_ 831 CellTemp40 : 1;
SIG_VALTYPE_ 355 Altitude : 1;
SIG_VALTYPE_ 355 PDOP : 1;
SIG_VALTYPE_ 356 Latitude : 1;
SIG_VALTYPE_ 357 Longitude : 1;
SIG_VALTYPE_ 357 LongReserv : 1;
SIG_VALTYPE_ 358 Speed : 1;
SIG_VALTYPE_ 358 SpeedReserv : 1;
SIG_VALTYPE_ 1284 Supply12v : 1;
SIG_VALTYPE_ 484 RawThrottle : 1;
